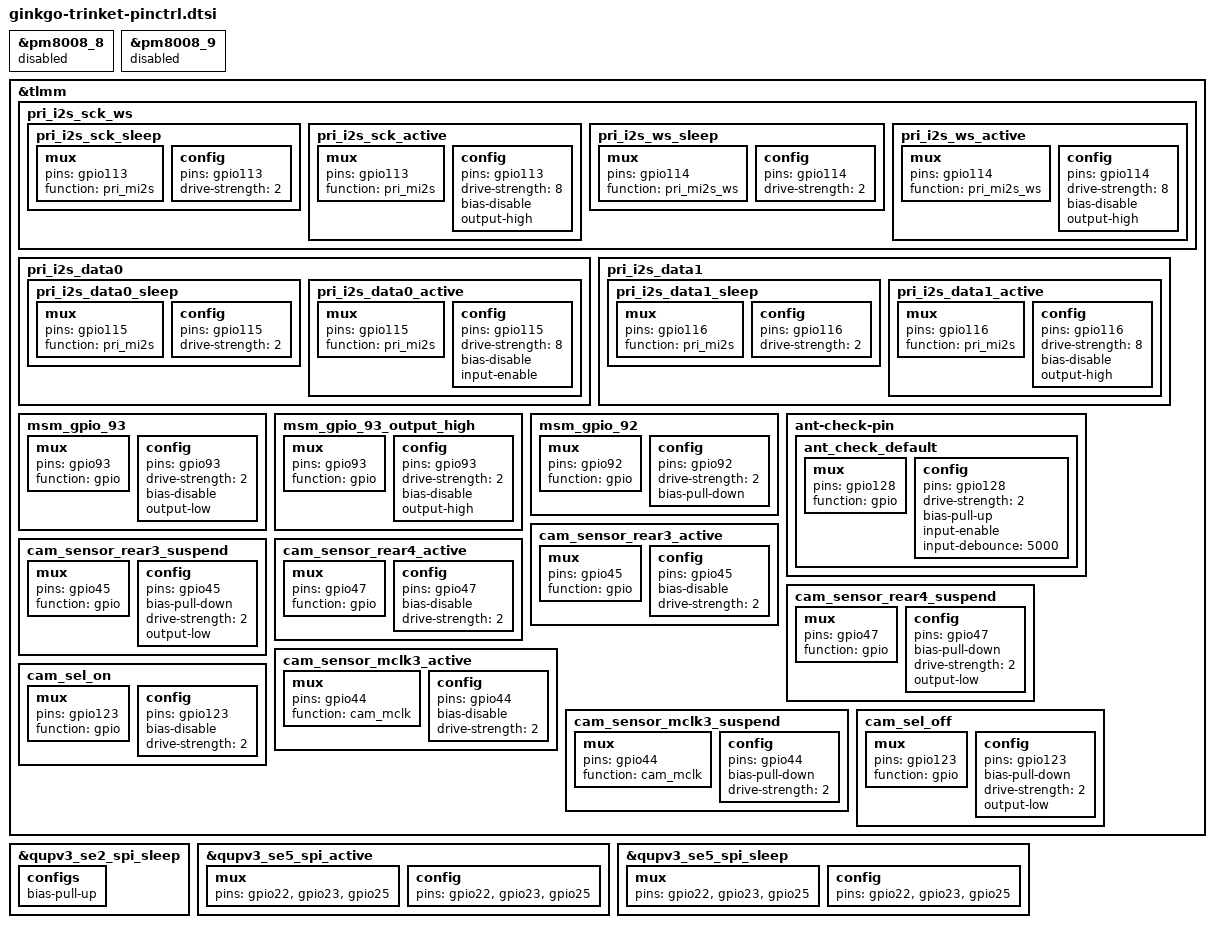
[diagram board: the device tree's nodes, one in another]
&pm8008_8 {
	status = "disabled";
};

&pm8008_9 {
	status = "disabled";
};

&tlmm {
	/delete-node/ wsa_swr_clk_pin;
	/delete-node/ wsa_swr_data_pin;
	/delete-node/ spkr_1_sd_n;
	/delete-node/ cdc_dmic01_clk_active;
	
	pri_i2s_sck_ws {
		pri_i2s_sck_sleep: pri_i2s_sck_sleep {
        	mux {
                pins = "gpio113";
                function = "pri_mi2s";
        	};

       		config {
                pins = "gpio113";
                drive-strength = <2>;   /* 2 mA */
        	};
		};
		pri_i2s_sck_active: pri_i2s_sck_active {
        	mux {
                pins = "gpio113";
                function = "pri_mi2s";
        	};

        	config {
                pins = "gpio113";
                drive-strength = <8>;   /* 8 mA */
                bias-disable;
                output-high;
        	};
		};

		pri_i2s_ws_sleep: pri_i2s_ws_sleep {
			mux {
				pins = "gpio114";
				function = "pri_mi2s_ws";
		  	};

		  	config {
				pins = "gpio114";
				drive-strength = <2>; /* 2 mA */
			};
		};
		pri_i2s_ws_active: pri_i2s_ws_active {
			mux {
				pins = "gpio114";
				function = "pri_mi2s_ws";
			};

			config {
				pins = "gpio114";
				drive-strength = <8>; /* 8 mA */
				bias-disable;
				output-high;
			};
		};
	};

	pri_i2s_data0 {
		pri_i2s_data0_sleep: pri_i2s_data0_sleep {
			mux {
				pins = "gpio115";
				function = "pri_mi2s";
    		};

    		config {
                pins = "gpio115";
                drive-strength = <2>;   /* 2 mA */
        	};
		};

		pri_i2s_data0_active: pri_i2s_data0_active {
        	mux {
                pins = "gpio115";
                function = "pri_mi2s";
        	};

        	config {
                pins = "gpio115";
                drive-strength = <8>;   /* 8 mA */
                bias-disable;
                input-enable;
        	};
		};
    };

	pri_i2s_data1 {
		pri_i2s_data1_sleep: pri_i2s_data1_sleep {
        	mux {
                pins = "gpio116";
                function = "pri_mi2s";
        	};

        	config {
                pins = "gpio116";
                drive-strength = <2>;   /* 2 mA */
        	};
		};

		pri_i2s_data1_active: pri_i2s_data1_active {
        	mux {
                pins = "gpio116";
                function = "pri_mi2s";
        	};

        	config {
                pins = "gpio116";
                drive-strength = <8>;   /* 8 mA */
                bias-disable;
                output-high;
        	};
		};
    };

	msm_gpio_93:msm_gpio_93 {
		mux {
			pins="gpio93";
			function= "gpio";
		};
		config {
			pins= "gpio93";
			drive-strength = <2>;
			bias-disable;
			output-low;
		};
	};

	msm_gpio_93_output_high:msm_gpio_93_output_high {
		mux {
			pins = "gpio93";
			function = "gpio";
		};
		config {
			pins = "gpio93";
			drive-strength = <2>;
			bias-disable;
			output-high;
		};
	};

	msm_gpio_92:msm_gpio_92{
		mux {
			pins = "gpio92";
			function = "gpio";
		};
		config {
			pins = "gpio92";
			drive-strength=<2>;
			bias-pull-down;
		};
	};

	ant-check-pin {
		ant_check_default: ant_check_default {
			mux {
				pins = "gpio128";
				function = "gpio";
			};
			config {
				pins = "gpio128";
				drive-strength = <2>;
				bias-pull-up;
				input-enable;
				input-debounce = <5000>;
			};
		};
	};

cam_sensor_rear3_active: cam_sensor_rear3_active {
		/* RESET3 */
		mux {
			pins = "gpio45";
			function = "gpio";
		};

		config {
			pins = "gpio45";
			bias-disable; /* No PULL */
			drive-strength = <2>; /* 2 MA */
		};
	};

	cam_sensor_rear3_suspend: cam_sensor_rear3_suspend {
		/* RESET3 */
		mux {
			pins = "gpio45";
			function = "gpio";
		};

		config {
			pins = "gpio45";
			bias-pull-down; /* PULL DOWN */
			drive-strength = <2>; /* 2 MA */
			output-low;
		};
	};

	cam_sensor_rear4_active: cam_sensor_rear4_active {
		/* RESET4 */
		mux {
			pins = "gpio47";
			function = "gpio";
		};

		config {
			pins = "gpio47";
			bias-disable; /* No PULL */
			drive-strength = <2>; /* 2 MA */
		};
	};

	cam_sensor_rear4_suspend: cam_sensor_rear4_suspend {
		/* RESET4 */
		mux {
			pins = "gpio47";
			function = "gpio";
		};

		config {
			pins = "gpio47";
			bias-pull-down; /* PULL DOWN */
			drive-strength = <2>; /* 2 MA */
			output-low;
		};
	};

	cam_sensor_mclk3_active: cam_sensor_mclk3_active {
		/* MCLK3 */
		mux {
			pins = "gpio44";
			function = "cam_mclk";
		};

		config {
			pins = "gpio44";
			bias-disable; /* No PULL */
			drive-strength = <2>; /* 2 MA */
		};
	};

	cam_sensor_mclk3_suspend: cam_sensor_mclk3_suspend {
		/* MCLK3 */
		mux {
			pins = "gpio44";
			function = "cam_mclk";
		};

		config {
			pins = "gpio44";
			bias-pull-down; /* PULL DOWN */
			drive-strength = <2>; /* 2 MA */
		};
	};


	cam_sel_on: cam_sel_on {
		/* sel */
		mux {
			pins = "gpio123";
			function = "gpio";
		};

		config {
			pins = "gpio123";
			bias-disable; /* No PULL */
			drive-strength = <2>; /* 2 MA */
		};
	};

	cam_sel_off: cam_sel_off {
		/* sel */
		mux {
			pins = "gpio123";
			function = "gpio";
		};

		config {
			pins = "gpio123";
			bias-pull-down; /* PULL DOWN */
			drive-strength = <2>; /* 2 MA */
			output-low;
		};
	};
};

&qupv3_se2_spi_sleep {
	configs {
		bias-pull-up;
	};
};

&qupv3_se5_spi_active {
	mux {
		pins = "gpio22", "gpio23", "gpio25";
	};
	config {
		pins = "gpio22", "gpio23", "gpio25";
	};
};

&qupv3_se5_spi_sleep {
	mux {
		pins = "gpio22", "gpio23", "gpio25";
	};
	config {
		pins = "gpio22", "gpio23", "gpio25";
	};
};
